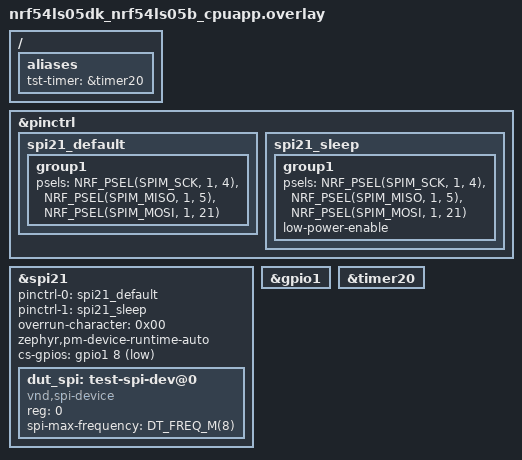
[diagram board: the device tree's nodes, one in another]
/*
 * Copyright (c) 2025 Nordic Semiconductor ASA
 *
 * SPDX-License-Identifier: LicenseRef-Nordic-5-Clause
 */

/* Required loopbacks:
 * P1.05 <-> P1.21
 */

/ {
	aliases {
		tst-timer = &timer20;
	};
};

&pinctrl {
	spi21_default: spi21_default {
		group1 {
			psels = <NRF_PSEL(SPIM_SCK, 1, 4)>,
				<NRF_PSEL(SPIM_MISO, 1, 5)>,
				<NRF_PSEL(SPIM_MOSI, 1, 21)>;
		};
	};

	spi21_sleep: spi21_sleep {
		group1 {
			psels = <NRF_PSEL(SPIM_SCK, 1, 4)>,
				<NRF_PSEL(SPIM_MISO, 1, 5)>,
				<NRF_PSEL(SPIM_MOSI, 1, 21)>;
			low-power-enable;
		};
	};
};

&spi21 {
	status = "okay";
	pinctrl-0 = <&spi21_default>;
	pinctrl-1 = <&spi21_sleep>;
	pinctrl-names = "default", "sleep";
	overrun-character = <0x00>;
	zephyr,pm-device-runtime-auto;
	cs-gpios = <&gpio1 8 GPIO_ACTIVE_LOW>;
	dut_spi: test-spi-dev@0 {
		compatible = "vnd,spi-device";
		reg = <0>;
		spi-max-frequency = <DT_FREQ_M(8)>;
	};
};

&gpio1 {
	status = "okay";
};

&timer20 {
	status = "okay";
};
